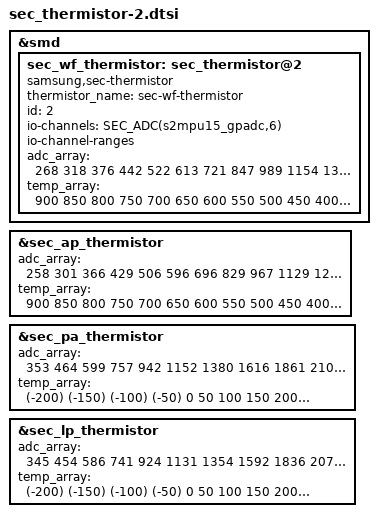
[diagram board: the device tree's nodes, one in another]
&smd{
	sec_wf_thermistor: sec_thermistor@2 {
		compatible = "samsung,sec-thermistor";
		status = "okay";
		thermistor_name = "sec-wf-thermistor";
		id = <2>;

		io-channels = SEC_ADC(s2mpu15_gpadc,6);
		io-channel-names = "adc-wf-temp";
		io-channel-ranges;
	};
};

/* /home/dpi/qb5_8814/workspace/P4_1716/android/kernel/kmodule/sec_pm/sec_thermistor/dts/sec_thermistor_lsi.m56x.dtsi */
&sec_ap_thermistor {
	adc_array = <258 301 366 429 506 596 696 829 967 1129
		1299 1509 1719 1951 2213 2453 2684 2920 3133 3317
		3482 3613 3729>;
	temp_array = <900 850 800 750 700 650 600 550 500 450
		400 350 300 250 200 150 100 50 0 (-50)
		(-100) (-150) (-200)>;
};

&sec_pa_thermistor {
	adc_array = <353 464 599 757 942 1152 1380 1616 1861 2107
		2340 2562 2762 2944 3107 3249 3377 3482 3573 3653
		3717 3777 3824>;
	temp_array = <(-200) (-150) (-100) (-50) 0 50 100 150 200 250
		300 350 400 450 500 550 600 650 700 750
		800 850 900>;
};

&sec_wf_thermistor {
	adc_array = <268 318 376 442 522 613 721 847 989 1154
		1337 1540 1760 1994 2238 2481 2719 2943 3152 3336
		3495 3627 3737>;
	temp_array = <900 850 800 750 700 650 600 550 500 450
		400 350 300 250 200 150 100 50 0 (-50)
		(-100) (-150) (-200)>;
};

&sec_lp_thermistor {
	adc_array = <345 454 586 741 924 1131 1354 1592 1836 2078
		2311 2533 2737 2924 3088 3232 3361 3469 3561 3642
		3708 3768 3817>;
	temp_array = <(-200) (-150) (-100) (-50) 0 50 100 150 200 250
		300 350 400 450 500 550 600 650 700 750
		800 850 900>;
};
